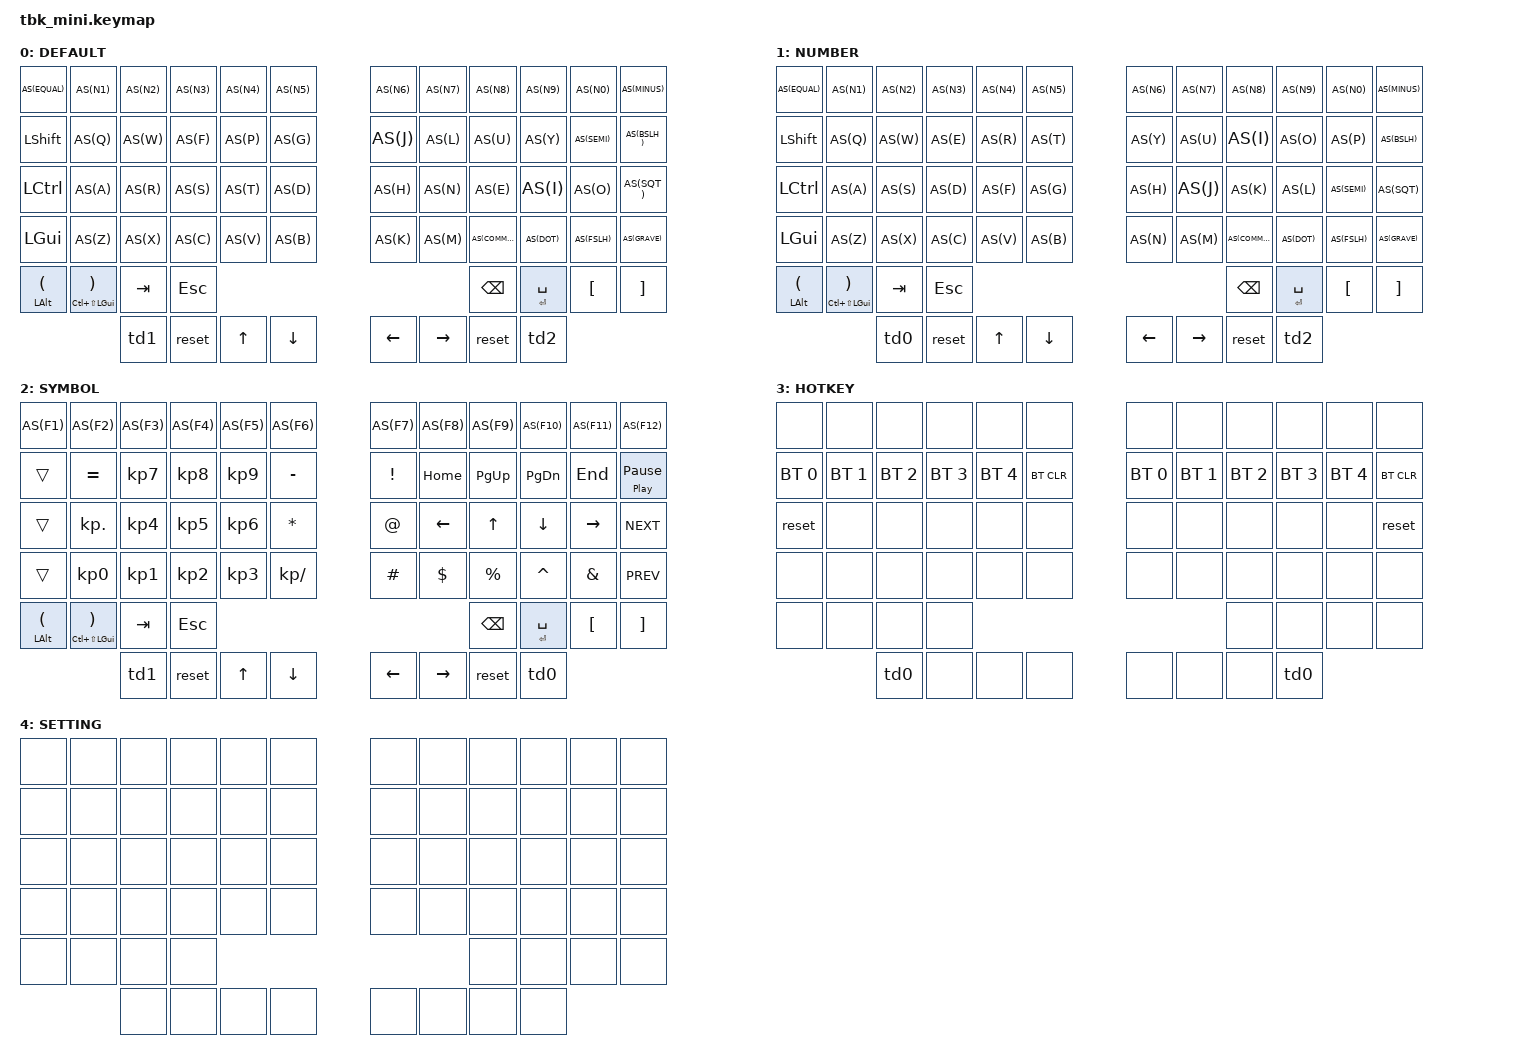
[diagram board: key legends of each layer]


#include <behaviors.dtsi>
#include <dt-bindings/zmk/keys.h>
#include <dt-bindings/zmk/bt.h>



#define DEFAULT 0
#define NUMBER  1
#define SYMBOL  2
#define HOTKEY  3
#define SETTING 4
#define AS(keycode) &as LS(keycode) keycode




/ {
        behaviors {
        td0: tap_dance_0 {
            compatible = "zmk,behavior-tap-dance";
            label = "TAP_DANCE_0";
            #binding-cells = <0>;
            tapping-term-ms = <200>;
            bindings = <&mo 0>, <&to 0>, <&to 0>;
        };
        td1: tap_dance_1 {
            compatible = "zmk,behavior-tap-dance";
            label = "TAP_DANCE_1";
            #binding-cells = <0>;
            tapping-term-ms = <200>;
            bindings = <&mo 1>, <&to 1>, <&to 3>;
        };
  
        td2: tap_dance_2 {
            compatible = "zmk,behavior-tap-dance";
            label = "TAP_DANCE_2";
            #binding-cells = <0>;
            tapping-term-ms = <200>;
            bindings = <&mo 2>, <&to 2>, <&to 2>;
   
        };
    };  

         behaviors {
       as: auto_shift {
        compatible = "zmk,behavior-hold-tap";
        label = "AUTO_SHIFT";
        #binding-cells = <2>;
        tapping-term-ms = <160>;
        quick-tap-ms = <0>;
        flavor = "tap-preferred";
        bindings = <&kp>, <&kp>;
                };
modcp: mod_copy {
        compatible = "zmk,behavior-mod-morph";
        label = "MOD_COPY";
        #binding-cells = <0>;
        bindings = <&as LS(C) C>, <&kp C>;
        mods = <(MOD_LGUI | MOD_RGUI)>;
};
  
        };


    macros {
        macro_phone: macro_phone {
            // 1351
            label = "MACRO_PHONE";
            compatible = "zmk,behavior-macro";
            #binding-cells = <0>;
            bindings
                = < &kp N1 &kp N3 &kp N5  &kp N1>
                ;
        };
        macro_email_q: macro_email_q {
            // 2894512440@qq.com
            label = "MACRO_EMAIL_QQ";
            compatible = "zmk,behavior-macro";
            #binding-cells = <0>;
            bindings 
                = < &kp N2 &kp N8 &kp N9 &kp N4 &kp N5 &kp  N1 &kp N2 &kp N4 &kp N4 &kp N0 
                    &kp AT &kp Q &kp Q &kp DOT  &kp C &kp O &kp M>
                ;
        };
        macro_email_g: macro_email_g {
            // 135115
            compatible = "zmk,behavior-macro";
            label = "MACRO_EMAIL_GMAIL";
            #binding-cells = <0>;
            bindings
                = < &kp N1 &kp N3 &kp N5  &kp N1 &kp N1 &kp N5 >
                ;
        };
       
    };
    



    keymap {
       compatible = "zmk,keymap";
      default_layer {
            label = "DEFAULT";
            bindings = <
   AS(EQUAL)  AS(N1) AS(N2) AS(N3) AS(N4) AS(N5)          AS(N6)  AS(N7) AS(N8)  AS(N9)  AS(N0)  AS(MINUS)  
   &kp LSHFT   AS(Q) AS(W) AS(F) AS(P) AS(G)              AS(J)  AS(L) AS(U)  AS(Y) AS(SEMI)  AS(BSLH )  
   &kp LCTRL AS(A) AS(R) AS(S) AS(T)  AS(D)         AS(H) AS(N) AS(E)  AS(I)  AS(O)  AS(SQT )  
 &kp LGUI   AS(Z) AS(X) AS(C) AS(V) AS(B)                  AS(K) AS(M)  AS(COMMA) AS(DOT) AS(FSLH)  AS(GRAVE)  
  &mt LALT LPAR  &mt LC(LS(LGUI)) RPAR &kp TAB &kp ESC       &kp BSPC  &mt ENTER SPACE  &kp LBKT  &kp RBKT
 &td1 &reset   &kp UP   &kp DOWN      &kp LEFT  &kp RIGHT &reset  &td2
            >;
        };


          number_layer {
            label = "NUMBER";
            bindings = <
   AS(EQUAL)  AS(N1) AS(N2) AS(N3) AS(N4) AS(N5)          AS(N6)  AS(N7) AS(N8)  AS(N9)  AS(N0)  AS(MINUS)  
   &kp LSHFT  AS(Q) AS(W) AS(E) AS(R) AS(T)           AS(Y) AS(U) AS(I)     AS(O)   AS(P)  AS(BSLH)  
   &kp LCTRL AS(A) AS(S) AS(D) AS(F) AS(G)            AS(H) AS(J) AS(K)     AS(L)  AS(SEMI)    AS(SQT) 
 &kp LGUI  AS(Z) AS(X) AS(C) AS(V) AS(B)             AS(N) AS(M) AS(COMMA) AS(DOT) AS(FSLH)  AS(GRAVE)  
  &mt LALT LPAR  &mt LC(LS(LGUI)) RPAR &kp TAB &kp ESC                    &kp BSPC  &mt ENTER SPACE  &kp LBKT  &kp RBKT
 &td0 &reset   &kp UP   &kp DOWN      &kp LEFT  &kp RIGHT &reset  &td2   
            >;
        };

        symbol_layer {
            label = "SYMBOL";
            bindings = <                                                                                         
    AS(F1)  AS(F2) AS(F3)  AS(F4)  AS(F5)  AS(F6)     AS(F7)  AS(F8) AS(F9)  AS(F10)  AS(F11)  AS(F12)      
    &trans  &kp EQUAL &kp KP_N7  &kp KP_N8  &kp KP_N9  &kp MINUS   &kp EXCL &kp HOME   &kp PG_UP &kp PG_DN  &kp END &mt C_PP PAUSE_BREAK
     &trans &kp KP_DOT  &kp KP_N4 &kp KP_N5  &kp KP_N6 &kp STAR         &kp AT  &kp LEFT &kp UP &kp DOWN &kp RIGHT &kp C_NEXT
    &trans  &kp KP_N0 &kp KP_N1 &kp KP_N2 &kp KP_N3 &kp KP_SLASH         &kp HASH &kp DLLR &kp PRCNT &kp CARET &kp AMPS &kp C_PREV
    &mt LALT LPAR  &mt LC(LS(LGUI)) RPAR &kp TAB &kp ESC                    &kp BSPC  &mt ENTER SPACE  &kp LBKT  &kp RBKT
   &td1 &reset   &kp UP   &kp DOWN      &kp LEFT  &kp RIGHT &reset  &td0        
         >;
        };


        hotkey_layer {
            label = "HOTKEY";
            bindings = <
   &none &none        &none        &none       &none &none                              &none &none &none &none &none &none
   &bt BT_SEL 0 &bt BT_SEL 1 &bt BT_SEL 2 &bt BT_SEL 3 &bt BT_SEL 4 &bt BT_CLR          &bt BT_SEL 0 &bt BT_SEL 1 &bt BT_SEL 2 &bt BT_SEL 3 &bt BT_SEL 4 &bt BT_CLR
   &reset  &none   &none     &none  &none     &none                                     &none     &none   &none &none &none &reset
   &none &none &none &none &none &none                                                &none  &none &none &none &none &none
   &none &none &none &none                                                              &none &none &none &none
   &td0 &none &none &none                                                              &none &none &none  &td0                                                    
            >;
        };
   




        setting_layer {
            label = "SETTING";
            bindings = <
        &none &none &none &none &none &none                                                  &none &none &none &none &none &none
        &none &none &none &none &none &none                                                  &none &none &none &none &none &none
        &none &none &none &none &none &none                                                  &none &none &none &none &none &none
         &none &none &none &none &none &none                                                  &none &none &none &none &none &none
         &none &none &none &none                                                              &none &none &none &none
          &none &none &none &none                                                              &none &none &none &none  
           >;
       };
   };
};
